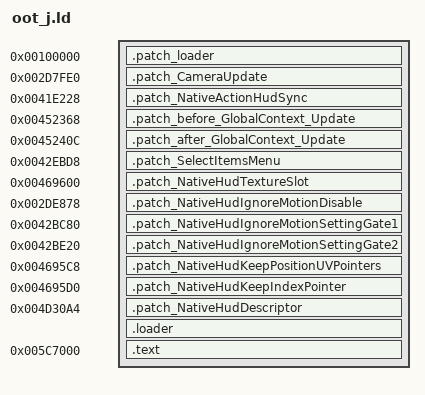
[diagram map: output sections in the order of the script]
OUTPUT_FORMAT("elf32-littlearm", "elf32-littlearm", "elf32-littlearm")
OUTPUT_ARCH(arm)
ENTRY(loader_patch)
SECTIONS
{
	. = 0x100000;
	.patch_loader 0x100000 : {
		*(.patch_loader)
	}

	.patch_CameraUpdate 0x2D7FE0 : {
	    * (.patch_CameraUpdate)
	}

	.patch_NativeActionHudSync 0x41E228 : {
		*(.patch_NativeActionHudSync)
	}

	.patch_before_GlobalContext_Update 0x452368 : {
		*(.patch_before_GlobalContext_Update)
	}

	.patch_after_GlobalContext_Update 0x45240C : {
		*(.patch_after_GlobalContext_Update)
	}

	.patch_SelectItemsMenu 0x42EBD8 : {
		*(.patch_SelectItemsMenu)
	}

	.patch_NativeHudTextureSlot 0x469600 : {
		*(.patch_NativeHudTextureSlot)
	}

	.patch_NativeHudIgnoreMotionDisable 0x2DE878 : {
		*(.patch_NativeHudIgnoreMotionDisable)
	}

	.patch_NativeHudIgnoreMotionSettingGate1 0x42BC80 : {
		*(.patch_NativeHudIgnoreMotionSettingGate1)
	}

	.patch_NativeHudIgnoreMotionSettingGate2 0x42BE20 : {
		*(.patch_NativeHudIgnoreMotionSettingGate2)
	}

	.patch_NativeHudKeepPositionUVPointers 0x4695C8 : {
		*(.patch_NativeHudKeepPositionUVPointers)
	}

	.patch_NativeHudKeepIndexPointer 0x4695D0 : {
		*(.patch_NativeHudKeepIndexPointer)
	}

	.patch_NativeHudDescriptor 0x4D30A4 : {
		*(.patch_NativeHudDescriptor)
	}

	. = 0x4C99A8;
	. = ALIGN(4);
	.loader : {
		*(.loader*)
	}

	. = 0x005C7000;
	.text : {
        __text_start = . ;
        *(.text)
        *(.text.*)
        __text_end  = . ;
        *(.rodata)
        *(.rodata.*)
        *(.data)
        *(.bss)
		*(COMMON)
	}

	/DISCARD/ : {
		*(.eh_frame*)
		*(.ARM.exidx*)
		*(.ARM.extab*)
	}
}
